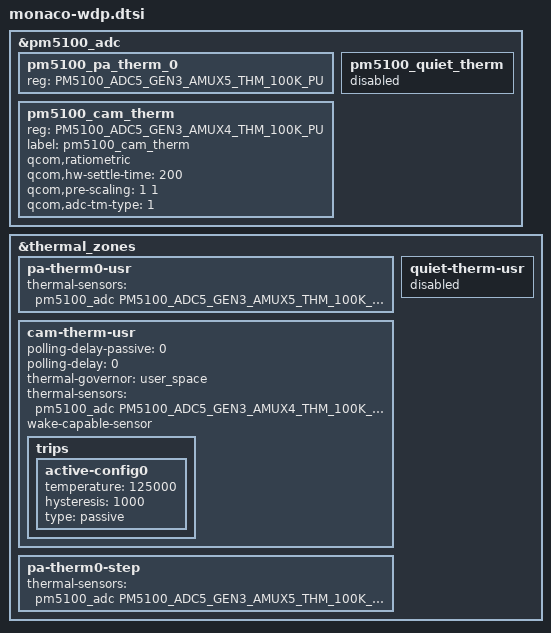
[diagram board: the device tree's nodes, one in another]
&pm5100_adc {
	pm5100_pa_therm_0 {
		reg = <PM5100_ADC5_GEN3_AMUX5_THM_100K_PU>;
	};

	pm5100_quiet_therm {
		status = "disabled";
	};

	pm5100_cam_therm {
		reg = <PM5100_ADC5_GEN3_AMUX4_THM_100K_PU>;
		label = "pm5100_cam_therm";
		qcom,ratiometric;
		qcom,hw-settle-time = <200>;
		qcom,pre-scaling = <1 1>;
		qcom,adc-tm-type = <1>;
	};
};

&thermal_zones {
	pa-therm0-usr {
		thermal-sensors = <&pm5100_adc PM5100_ADC5_GEN3_AMUX5_THM_100K_PU>;
	};

	quiet-therm-usr {
		status = "disabled";
	};

	cam-therm-usr {
		polling-delay-passive = <0>;
		polling-delay = <0>;
		thermal-governor = "user_space";
		thermal-sensors = <&pm5100_adc PM5100_ADC5_GEN3_AMUX4_THM_100K_PU>;
		wake-capable-sensor;
		trips {
			active-config0 {
				temperature = <125000>;
				hysteresis = <1000>;
				type = "passive";
			};
		};
	};

	pa-therm0-step {
		thermal-sensors = <&pm5100_adc PM5100_ADC5_GEN3_AMUX5_THM_100K_PU>;
		status = "ok";
	};
};
